# MIMXRT1011 register map
Vendor: nxp.com; File version: 1.0
CPU: CM7 r0p1, little endian, MPU, FPU, VTOR, 4 interrupt priority bits
Registers are 32-bit, read-write, reset 0x0 unless marked. A register's access mark holds for its fields unless they carry their own. Offsets are from the block's base; [hi:lo] are bit positions; {n}, {i} and the like mark numbered series; 'fields as' and 'values as' point back to an identical list.

## IOMUXC (part 2 of 2)
Base 0x401F8000; register names take the prefix IOMUXC_
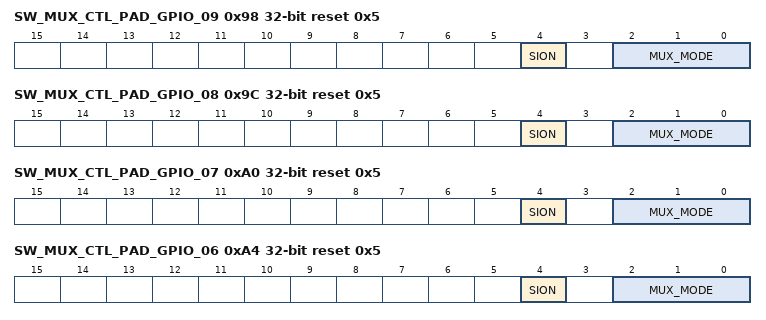
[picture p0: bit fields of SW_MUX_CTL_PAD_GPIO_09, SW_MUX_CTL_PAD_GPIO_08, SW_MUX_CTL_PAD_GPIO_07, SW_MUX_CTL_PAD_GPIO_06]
0x98 SW_MUX_CTL_PAD_GPIO_09 reset 0x5 — SW_MUX_CTL_PAD_GPIO_09 SW MUX Control Register
  [4] SION — Software Input On Field.
    0=DISABLED (Input Path is determined by functionality); 1=ENABLED (Force input path of pad GPIO_09)
  [2:0] MUX_MODE — MUX Mode Select Field.
    0=ALT0 (Select mux mode: ALT0 mux port: LPUART1_RXD of instance: LPUART1); 1=ALT1 (Select mux mode: ALT1 mux port: WDOG1_B of instance: WDOG1); 2=ALT2 (Select mux mode: ALT2 mux port: FLEXSPI_A_SS1_B of instance: FLEXSPI); 3=ALT3 (Select mux mode: ALT3 mux port: LPI2C2_SDA of instance: LPI2C2); 4=ALT4 (Select mux mode: ALT4 mux port: FLEXIO1_IO01 of instance: FLEXIO1); 5=ALT5 (Select mux mode: ALT5 mux port: GPIOMUX_IO09 of instance: GPIOMUX); 6=ALT6 (Select mux mode: ALT6 mux port: SPDIF_SR_CLK of instance: SPDIF)
0x9C SW_MUX_CTL_PAD_GPIO_08 reset 0x5 — SW_MUX_CTL_PAD_GPIO_08 SW MUX Control Register
  [4] SION — Software Input On Field.
    0=DISABLED (Input Path is determined by functionality); 1=ENABLED (Force input path of pad GPIO_08)
  [2:0] MUX_MODE — MUX Mode Select Field.
    0=ALT0 (Select mux mode: ALT0 mux port: SAI1_MCLK of instance: SAI1); 1=ALT1 (Select mux mode: ALT1 mux port: GPT1_CLK of instance: GPT1); 2=ALT2 (Select mux mode: ALT2 mux port: FLEXPWM1_PWM3_A of instance: FLEXPWM1); 3=ALT3 (Select mux mode: ALT3 mux port: LPUART3_TXD of instance: LPUART3); 4=ALT4 (Select mux mode: ALT4 mux port: FLEXIO1_IO00 of instance: FLEXIO1); 5=ALT5 (Select mux mode: ALT5 mux port: GPIOMUX_IO08 of instance: GPIOMUX); 6=ALT6 (Select mux mode: ALT6 mux port: LPUART1_CTS_B of instance: LPUART1)
0xA0 SW_MUX_CTL_PAD_GPIO_07 reset 0x5 — SW_MUX_CTL_PAD_GPIO_07 SW MUX Control Register
  [4] SION — Software Input On Field.
    0=DISABLED (Input Path is determined by functionality); 1=ENABLED (Force input path of pad GPIO_07)
  [2:0] MUX_MODE — MUX Mode Select Field.
    0=ALT0 (Select mux mode: ALT0 mux port: SAI1_TX_SYNC of instance: SAI1); 1=ALT1 (Select mux mode: ALT1 mux port: GPT1_COMPARE1 of instance: GPT1); 2=ALT2 (Select mux mode: ALT2 mux port: FLEXPWM1_PWM3_B of instance: FLEXPWM1); 3=ALT3 (Select mux mode: ALT3 mux port: LPUART3_RXD of instance: LPUART3); 4=ALT4 (Select mux mode: ALT4 mux port: SPDIF_LOCK of instance: SPDIF); 5=ALT5 (Select mux mode: ALT5 mux port: GPIOMUX_IO07 of instance: GPIOMUX); 6=ALT6 (Select mux mode: ALT6 mux port: LPUART1_RTS_B of instance: LPUART1)
0xA4 SW_MUX_CTL_PAD_GPIO_06 reset 0x5 — SW_MUX_CTL_PAD_GPIO_06 SW MUX Control Register
  [4] SION — Software Input On Field.
    0=DISABLED (Input Path is determined by functionality); 1=ENABLED (Force input path of pad GPIO_06)
  [2:0] MUX_MODE — MUX Mode Select Field.
    0=ALT0 (Select mux mode: ALT0 mux port: SAI1_TX_BCLK of instance: SAI1); 1=ALT1 (Select mux mode: ALT1 mux port: GPT1_CAPTURE1 of instance: GPT1); 2=ALT2 (Select mux mode: ALT2 mux port: FLEXPWM1_PWM2_A of instance: FLEXPWM1); 3=ALT3 (Select mux mode: ALT3 mux port: LPUART4_TXD of instance: LPUART4); 4=ALT4 (Select mux mode: ALT4 mux port: SPDIF_EXT_CLK of instance: SPDIF); 5=ALT5 (Select mux mode: ALT5 mux port: GPIOMUX_IO06 of instance: GPIOMUX)
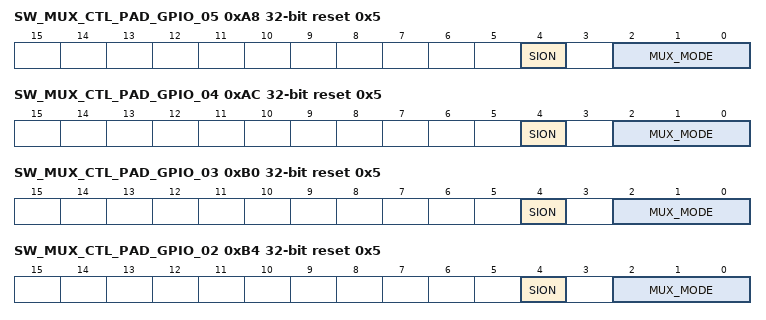
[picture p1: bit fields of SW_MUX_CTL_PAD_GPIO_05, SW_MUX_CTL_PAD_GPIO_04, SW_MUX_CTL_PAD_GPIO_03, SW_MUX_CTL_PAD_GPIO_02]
0xA8 SW_MUX_CTL_PAD_GPIO_05 reset 0x5 — SW_MUX_CTL_PAD_GPIO_05 SW MUX Control Register
  [4] SION — Software Input On Field.
    0=DISABLED (Input Path is determined by functionality); 1=ENABLED (Force input path of pad GPIO_05)
  [2:0] MUX_MODE — MUX Mode Select Field.
    0=ALT0 (Select mux mode: ALT0 mux port: SAI1_TX_DATA01 of instance: SAI1); 1=ALT1 (Select mux mode: ALT1 mux port: GPT1_COMPARE2 of instance: GPT1); 2=ALT2 (Select mux mode: ALT2 mux port: FLEXPWM1_PWM2_B of instance: FLEXPWM1); 3=ALT3 (Select mux mode: ALT3 mux port: LPUART4_RXD of instance: LPUART4); 4=ALT4 (Select mux mode: ALT4 mux port: SPDIF_OUT of instance: SPDIF); 5=ALT5 (Select mux mode: ALT5 mux port: GPIOMUX_IO05 of instance: GPIOMUX)
0xAC SW_MUX_CTL_PAD_GPIO_04 reset 0x5 — SW_MUX_CTL_PAD_GPIO_04 SW MUX Control Register
  [4] SION — Software Input On Field.
    0=DISABLED (Input Path is determined by functionality); 1=ENABLED (Force input path of pad GPIO_04)
  [2:0] MUX_MODE — MUX Mode Select Field.
    0=ALT0 (Select mux mode: ALT0 mux port: SAI1_TX_DATA00 of instance: SAI1); 1=ALT1 (Select mux mode: ALT1 mux port: GPT1_CAPTURE2 of instance: GPT1); 2=ALT2 (Select mux mode: ALT2 mux port: FLEXPWM1_PWM1_A of instance: FLEXPWM1); 4=ALT4 (Select mux mode: ALT4 mux port: SPDIF_IN of instance: SPDIF); 5=ALT5 (Select mux mode: ALT5 mux port: GPIOMUX_IO04 of instance: GPIOMUX)
0xB0 SW_MUX_CTL_PAD_GPIO_03 reset 0x5 — SW_MUX_CTL_PAD_GPIO_03 SW MUX Control Register
  [4] SION — Software Input On Field.
    0=DISABLED (Input Path is determined by functionality); 1=ENABLED (Force input path of pad GPIO_03)
  [2:0] MUX_MODE — MUX Mode Select Field.
    0=ALT0 (Select mux mode: ALT0 mux port: SAI1_RX_DATA00 of instance: SAI1); 1=ALT1 (Select mux mode: ALT1 mux port: GPT1_COMPARE3 of instance: GPT1); 2=ALT2 (Select mux mode: ALT2 mux port: FLEXPWM1_PWM1_B of instance: FLEXPWM1); 4=ALT4 (Select mux mode: ALT4 mux port: SPDIF_SR_CLK of instance: SPDIF); 5=ALT5 (Select mux mode: ALT5 mux port: GPIOMUX_IO03 of instance: GPIOMUX)
0xB4 SW_MUX_CTL_PAD_GPIO_02 reset 0x5 — SW_MUX_CTL_PAD_GPIO_02 SW MUX Control Register
  [4] SION — Software Input On Field.
    0=DISABLED (Input Path is determined by functionality); 1=ENABLED (Force input path of pad GPIO_02)
  [2:0] MUX_MODE — MUX Mode Select Field.
    0=ALT0 (Select mux mode: ALT0 mux port: SAI1_RX_SYNC of instance: SAI1); 1=ALT1 (Select mux mode: ALT1 mux port: WDOG2_B of instance: WDOG2); 2=ALT2 (Select mux mode: ALT2 mux port: FLEXPWM1_PWM0_A of instance: FLEXPWM1); 3=ALT3 (Select mux mode: ALT3 mux port: LPI2C1_SCL of instance: LPI2C1); 4=ALT4 (Select mux mode: ALT4 mux port: KPP_COL03 of instance: KPP); 5=ALT5 (Select mux mode: ALT5 mux port: GPIOMUX_IO02 of instance: GPIOMUX)
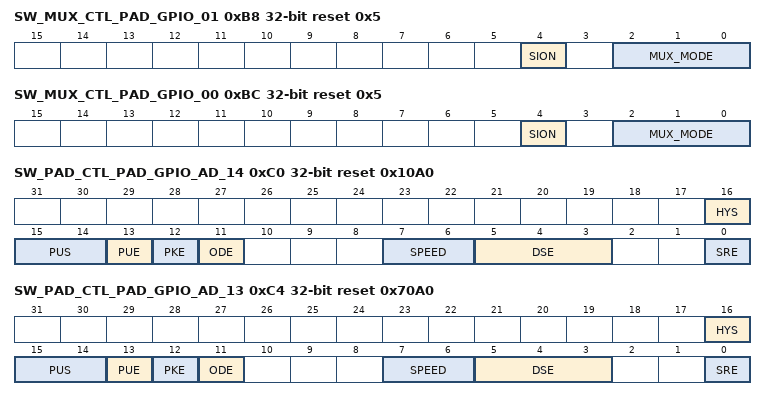
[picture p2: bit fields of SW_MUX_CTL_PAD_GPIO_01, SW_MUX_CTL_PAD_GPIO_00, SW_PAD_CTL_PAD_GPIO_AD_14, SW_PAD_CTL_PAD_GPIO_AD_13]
0xB8 SW_MUX_CTL_PAD_GPIO_01 reset 0x5 — SW_MUX_CTL_PAD_GPIO_01 SW MUX Control Register
  [4] SION — Software Input On Field.
    0=DISABLED (Input Path is determined by functionality); 1=ENABLED (Force input path of pad GPIO_01)
  [2:0] MUX_MODE — MUX Mode Select Field.
    0=ALT0 (Select mux mode: ALT0 mux port: SAI1_RX_BCLK of instance: SAI1); 1=ALT1 (Select mux mode: ALT1 mux port: WDOG1_ANY of instance: WDOG1); 2=ALT2 (Select mux mode: ALT2 mux port: FLEXPWM1_PWM0_B of instance: FLEXPWM1); 3=ALT3 (Select mux mode: ALT3 mux port: LPI2C1_SDA of instance: LPI2C1); 4=ALT4 (Select mux mode: ALT4 mux port: KPP_ROW03 of instance: KPP); 5=ALT5 (Select mux mode: ALT5 mux port: GPIOMUX_IO01 of instance: GPIOMUX)
0xBC SW_MUX_CTL_PAD_GPIO_00 reset 0x5 — SW_MUX_CTL_PAD_GPIO_00 SW MUX Control Register
  [4] SION — Software Input On Field.
    0=DISABLED (Input Path is determined by functionality); 1=ENABLED (Force input path of pad GPIO_00)
  [2:0] MUX_MODE — MUX Mode Select Field.
    0=ALT0 (Select mux mode: ALT0 mux port: FLEXSPI_B_DQS of instance: FLEXSPI); 1=ALT1 (Select mux mode: ALT1 mux port: SAI3_MCLK of instance: SAI3); 2=ALT2 (Select mux mode: ALT2 mux port: LPSPI2_PCS3 of instance: LPSPI2); 3=ALT3 (Select mux mode: ALT3 mux port: LPSPI1_PCS3 of instance: LPSPI1); 4=ALT4 (Select mux mode: ALT4 mux port: PIT_TRIGGER00 of instance: PIT); 5=ALT5 (Select mux mode: ALT5 mux port: GPIOMUX_IO00 of instance: GPIOMUX)
0xC0 SW_PAD_CTL_PAD_GPIO_AD_14 reset 0x10A0 — SW_PAD_CTL_PAD_GPIO_AD_14 SW PAD Control Register
  [16] HYS — Hyst. Enable Field
    0=HYS_0_Hysteresis_Disabled (Hysteresis Disabled); 1=HYS_1_Hysteresis_Enabled (Hysteresis Enabled)
  [15:14] PUS — Pull Up / Down Config. Field
    0=PUS_0_100K_Ohm_Pull_Down (100K Ohm Pull Down); 1=PUS_1_47K_Ohm_Pull_Up (47K Ohm Pull Up); 2=PUS_2_100K_Ohm_Pull_Up (100K Ohm Pull Up); 3=PUS_3_22K_Ohm_Pull_Up (22K Ohm Pull Up)
  [13] PUE — Pull / Keep Select Field
    0=PUE_0_Keeper (Keeper); 1=PUE_1_Pull (Pull)
  [12] PKE — Pull / Keep Enable Field
    0=PKE_0_Pull_Keeper_Disabled (Pull/Keeper Disabled); 1=PKE_1_Pull_Keeper_Enabled (Pull/Keeper Enabled)
  [11] ODE — Open Drain Enable Field
    0=ODE_0_Open_Drain_Disabled (Open Drain Disabled); 1=ODE_1_Open_Drain_Enabled (Open Drain Enabled)
  [7:6] SPEED
    0=SPEED_0_low_50MHz (low(50MHz)); 1=SPEED_1_medium_100MHz (medium(100MHz)); 2=SPEED_2_fast_150MHz (fast(150MHz)); 3=SPEED_3_max_200MHz (max(200MHz))
  [5:3] DSE — Drive Strength Field
    0=DSE_0_output_driver_disabled_ (output driver disabled;); 1=DSE_1_R0_150_Ohm___3_3V__260_Ohm_1_8V__240_Ohm_for_DDR_ (R0(150 Ohm @ 3.3V, 260 Ohm@1.8V, 240 Ohm for DDR)); {v}=DSE_{v}_R0_{v} (R0/{v}) (v=2..7)
  [0] SRE — Slew Rate Field
    0=SRE_0_Slow_Slew_Rate (Slow Slew Rate); 1=SRE_1_Fast_Slew_Rate (Fast Slew Rate)
0xC4 SW_PAD_CTL_PAD_GPIO_AD_13 reset 0x70A0 — SW_PAD_CTL_PAD_GPIO_AD_13 SW PAD Control Register
  fields as SW_PAD_CTL_PAD_GPIO_AD_14
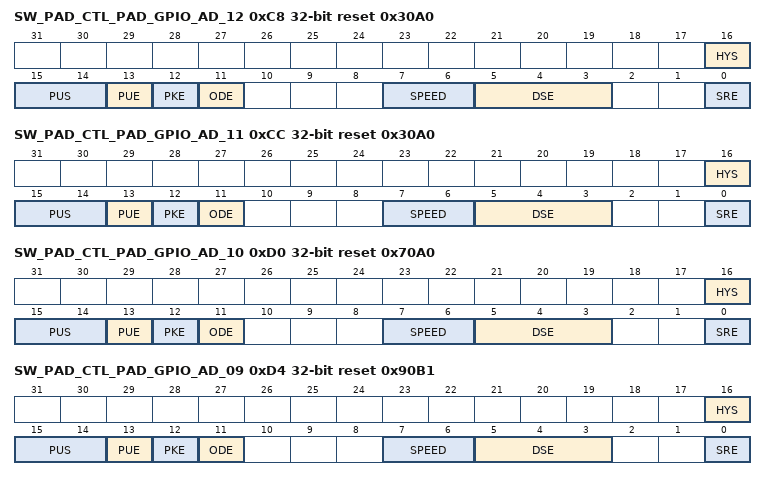
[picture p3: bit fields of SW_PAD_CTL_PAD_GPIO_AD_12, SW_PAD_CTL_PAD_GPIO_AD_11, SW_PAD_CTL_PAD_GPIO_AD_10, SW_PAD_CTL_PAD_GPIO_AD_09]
0xC8 SW_PAD_CTL_PAD_GPIO_AD_12 reset 0x30A0 — SW_PAD_CTL_PAD_GPIO_AD_12 SW PAD Control Register
  fields as SW_PAD_CTL_PAD_GPIO_AD_14
0xCC SW_PAD_CTL_PAD_GPIO_AD_11 reset 0x30A0 — SW_PAD_CTL_PAD_GPIO_AD_11 SW PAD Control Register
  fields as SW_PAD_CTL_PAD_GPIO_AD_14
0xD0 SW_PAD_CTL_PAD_GPIO_AD_10 reset 0x70A0 — SW_PAD_CTL_PAD_GPIO_AD_10 SW PAD Control Register
  fields as SW_PAD_CTL_PAD_GPIO_AD_14
0xD4 SW_PAD_CTL_PAD_GPIO_AD_09 reset 0x90B1 — SW_PAD_CTL_PAD_GPIO_AD_09 SW PAD Control Register
  fields as SW_PAD_CTL_PAD_GPIO_AD_14
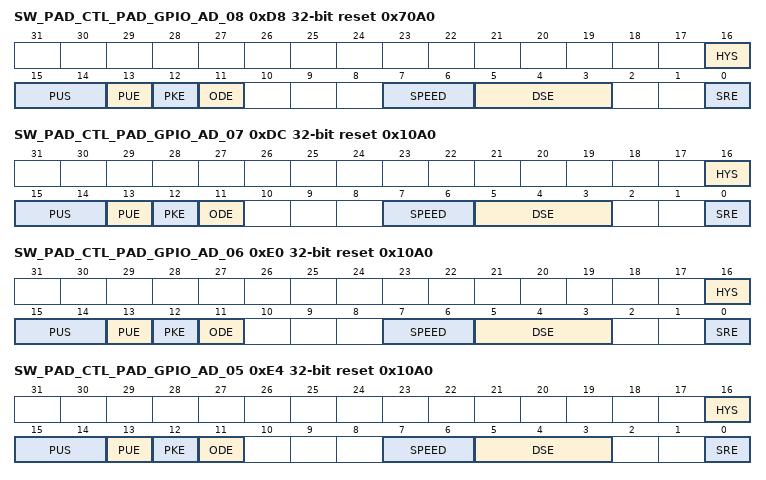
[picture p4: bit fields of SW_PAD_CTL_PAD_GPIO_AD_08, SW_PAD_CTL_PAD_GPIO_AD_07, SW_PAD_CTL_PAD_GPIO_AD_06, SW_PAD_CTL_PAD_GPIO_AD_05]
0xD8 SW_PAD_CTL_PAD_GPIO_AD_08 reset 0x70A0 — SW_PAD_CTL_PAD_GPIO_AD_08 SW PAD Control Register
  fields as SW_PAD_CTL_PAD_GPIO_AD_14
0xDC SW_PAD_CTL_PAD_GPIO_AD_07 reset 0x10A0 — SW_PAD_CTL_PAD_GPIO_AD_07 SW PAD Control Register
  fields as SW_PAD_CTL_PAD_GPIO_AD_14
0xE0 SW_PAD_CTL_PAD_GPIO_AD_06 reset 0x10A0 — SW_PAD_CTL_PAD_GPIO_AD_06 SW PAD Control Register
  fields as SW_PAD_CTL_PAD_GPIO_AD_14
0xE4 SW_PAD_CTL_PAD_GPIO_AD_05 reset 0x10A0 — SW_PAD_CTL_PAD_GPIO_AD_05 SW PAD Control Register
  fields as SW_PAD_CTL_PAD_GPIO_AD_14
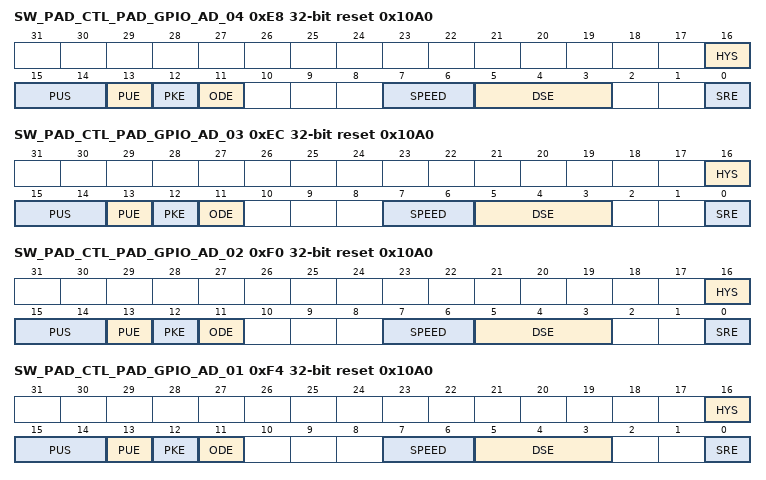
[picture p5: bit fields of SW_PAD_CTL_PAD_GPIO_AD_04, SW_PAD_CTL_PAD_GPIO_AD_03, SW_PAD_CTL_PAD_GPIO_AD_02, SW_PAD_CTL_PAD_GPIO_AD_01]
0xE8 SW_PAD_CTL_PAD_GPIO_AD_04 reset 0x10A0 — SW_PAD_CTL_PAD_GPIO_AD_04 SW PAD Control Register
  fields as SW_PAD_CTL_PAD_GPIO_AD_14
0xEC SW_PAD_CTL_PAD_GPIO_AD_03 reset 0x10A0 — SW_PAD_CTL_PAD_GPIO_AD_03 SW PAD Control Register
  fields as SW_PAD_CTL_PAD_GPIO_AD_14
0xF0 SW_PAD_CTL_PAD_GPIO_AD_02 reset 0x10A0 — SW_PAD_CTL_PAD_GPIO_AD_02 SW PAD Control Register
  fields as SW_PAD_CTL_PAD_GPIO_AD_14
0xF4 SW_PAD_CTL_PAD_GPIO_AD_01 reset 0x10A0 — SW_PAD_CTL_PAD_GPIO_AD_01 SW PAD Control Register
  fields as SW_PAD_CTL_PAD_GPIO_AD_14
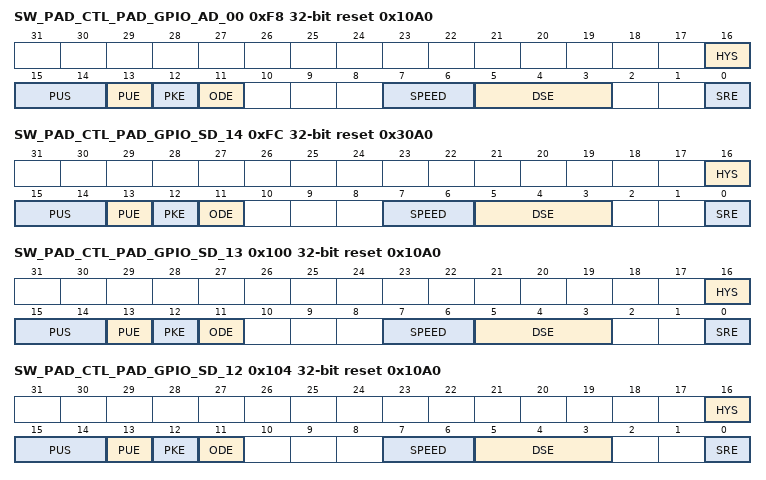
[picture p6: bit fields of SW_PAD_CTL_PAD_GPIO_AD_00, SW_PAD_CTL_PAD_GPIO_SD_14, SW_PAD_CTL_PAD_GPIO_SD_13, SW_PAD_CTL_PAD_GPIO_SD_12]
0xF8 SW_PAD_CTL_PAD_GPIO_AD_00 reset 0x10A0 — SW_PAD_CTL_PAD_GPIO_AD_00 SW PAD Control Register
  fields as SW_PAD_CTL_PAD_GPIO_AD_14
0xFC SW_PAD_CTL_PAD_GPIO_SD_14 reset 0x30A0 — SW_PAD_CTL_PAD_GPIO_SD_14 SW PAD Control Register
  fields as SW_PAD_CTL_PAD_GPIO_AD_14
0x100 SW_PAD_CTL_PAD_GPIO_SD_13 reset 0x10A0 — SW_PAD_CTL_PAD_GPIO_SD_13 SW PAD Control Register
  fields as SW_PAD_CTL_PAD_GPIO_AD_14
0x104 SW_PAD_CTL_PAD_GPIO_SD_12 reset 0x10A0 — SW_PAD_CTL_PAD_GPIO_SD_12 SW PAD Control Register
  fields as SW_PAD_CTL_PAD_GPIO_AD_14
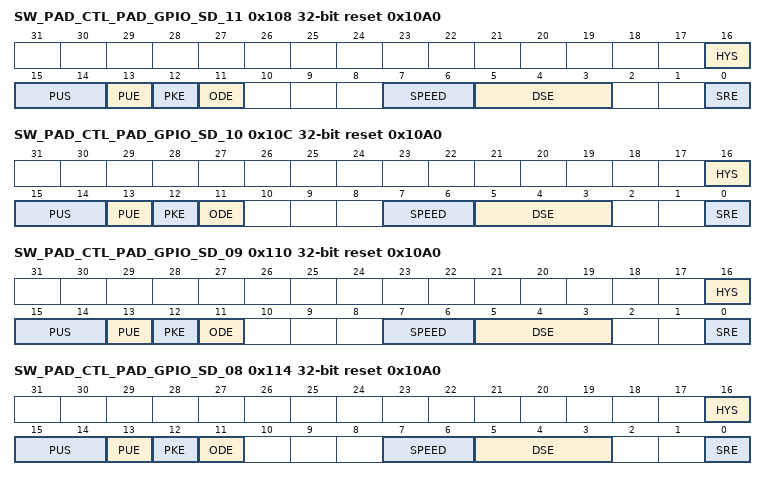
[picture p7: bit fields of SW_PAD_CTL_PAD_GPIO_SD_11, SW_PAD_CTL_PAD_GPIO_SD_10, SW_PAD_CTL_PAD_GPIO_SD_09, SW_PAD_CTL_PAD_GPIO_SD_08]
0x108 SW_PAD_CTL_PAD_GPIO_SD_11 reset 0x10A0 — SW_PAD_CTL_PAD_GPIO_SD_11 SW PAD Control Register
  fields as SW_PAD_CTL_PAD_GPIO_AD_14
0x10C SW_PAD_CTL_PAD_GPIO_SD_10 reset 0x10A0 — SW_PAD_CTL_PAD_GPIO_SD_10 SW PAD Control Register
  fields as SW_PAD_CTL_PAD_GPIO_AD_14
0x110 SW_PAD_CTL_PAD_GPIO_SD_09 reset 0x10A0 — SW_PAD_CTL_PAD_GPIO_SD_09 SW PAD Control Register
  fields as SW_PAD_CTL_PAD_GPIO_AD_14
0x114 SW_PAD_CTL_PAD_GPIO_SD_08 reset 0x10A0 — SW_PAD_CTL_PAD_GPIO_SD_08 SW PAD Control Register
  fields as SW_PAD_CTL_PAD_GPIO_AD_14
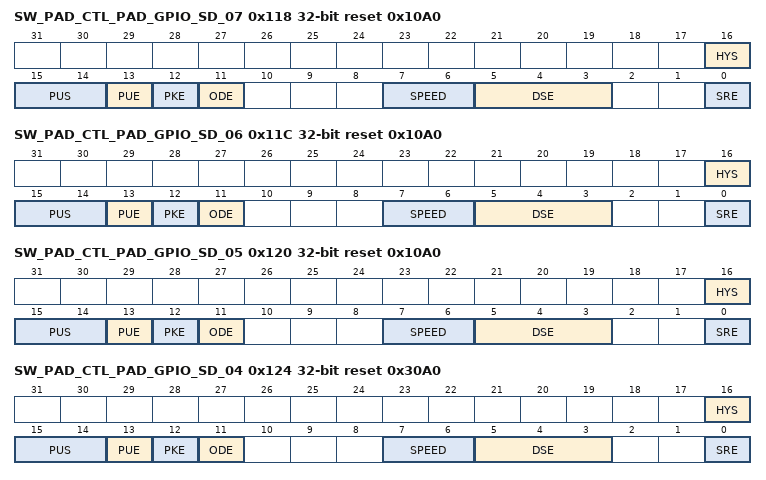
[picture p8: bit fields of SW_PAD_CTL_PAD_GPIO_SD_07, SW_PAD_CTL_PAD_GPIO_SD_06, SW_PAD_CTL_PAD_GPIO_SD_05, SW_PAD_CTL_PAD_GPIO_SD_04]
0x118 SW_PAD_CTL_PAD_GPIO_SD_07 reset 0x10A0 — SW_PAD_CTL_PAD_GPIO_SD_07 SW PAD Control Register
  fields as SW_PAD_CTL_PAD_GPIO_AD_14
0x11C SW_PAD_CTL_PAD_GPIO_SD_06 reset 0x10A0 — SW_PAD_CTL_PAD_GPIO_SD_06 SW PAD Control Register
  fields as SW_PAD_CTL_PAD_GPIO_AD_14
0x120 SW_PAD_CTL_PAD_GPIO_SD_05 reset 0x10A0 — SW_PAD_CTL_PAD_GPIO_SD_05 SW PAD Control Register
  fields as SW_PAD_CTL_PAD_GPIO_AD_14
0x124 SW_PAD_CTL_PAD_GPIO_SD_04 reset 0x30A0 — SW_PAD_CTL_PAD_GPIO_SD_04 SW PAD Control Register
  fields as SW_PAD_CTL_PAD_GPIO_AD_14
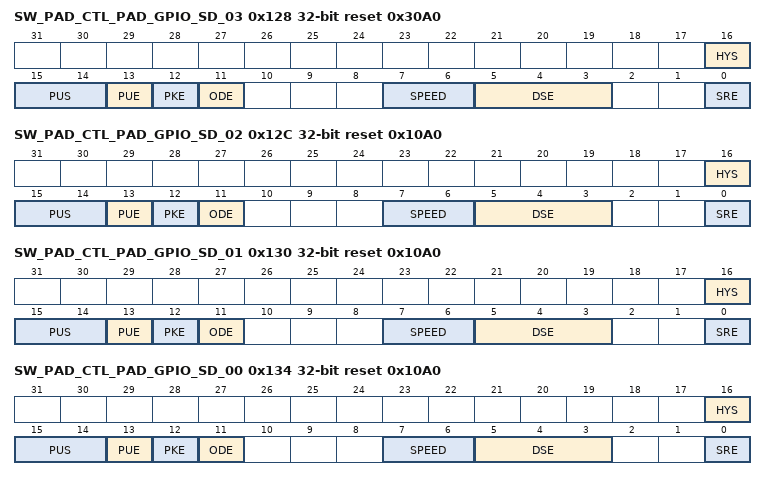
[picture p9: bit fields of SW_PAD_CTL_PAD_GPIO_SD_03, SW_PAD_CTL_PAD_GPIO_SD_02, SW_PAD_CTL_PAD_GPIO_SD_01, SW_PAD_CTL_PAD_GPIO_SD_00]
0x128 SW_PAD_CTL_PAD_GPIO_SD_03 reset 0x30A0 — SW_PAD_CTL_PAD_GPIO_SD_03 SW PAD Control Register
  fields as SW_PAD_CTL_PAD_GPIO_AD_14
0x12C SW_PAD_CTL_PAD_GPIO_SD_02 reset 0x10A0 — SW_PAD_CTL_PAD_GPIO_SD_02 SW PAD Control Register
  fields as SW_PAD_CTL_PAD_GPIO_AD_14
0x130 SW_PAD_CTL_PAD_GPIO_SD_01 reset 0x10A0 — SW_PAD_CTL_PAD_GPIO_SD_01 SW PAD Control Register
  fields as SW_PAD_CTL_PAD_GPIO_AD_14
0x134 SW_PAD_CTL_PAD_GPIO_SD_00 reset 0x10A0 — SW_PAD_CTL_PAD_GPIO_SD_00 SW PAD Control Register
  fields as SW_PAD_CTL_PAD_GPIO_AD_14
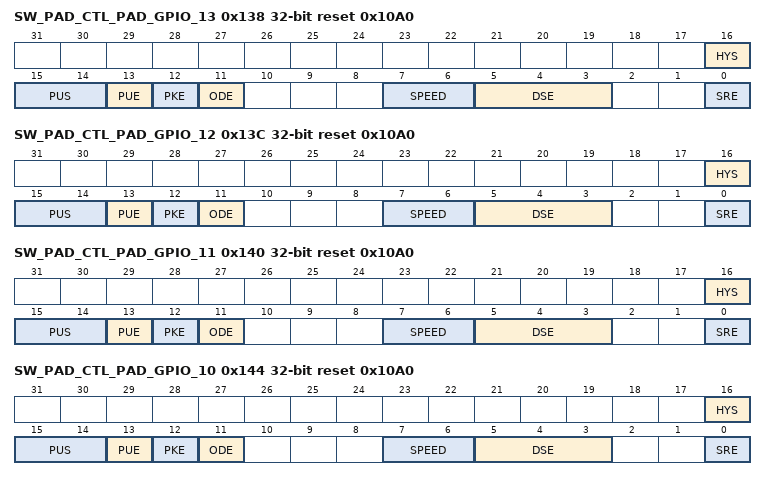
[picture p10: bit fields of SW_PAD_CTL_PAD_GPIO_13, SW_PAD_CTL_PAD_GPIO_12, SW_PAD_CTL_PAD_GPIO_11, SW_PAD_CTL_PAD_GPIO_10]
0x138 SW_PAD_CTL_PAD_GPIO_13 reset 0x10A0 — SW_PAD_CTL_PAD_GPIO_13 SW PAD Control Register
  fields as SW_PAD_CTL_PAD_GPIO_AD_14
0x13C SW_PAD_CTL_PAD_GPIO_12 reset 0x10A0 — SW_PAD_CTL_PAD_GPIO_12 SW PAD Control Register
  fields as SW_PAD_CTL_PAD_GPIO_AD_14
0x140 SW_PAD_CTL_PAD_GPIO_11 reset 0x10A0 — SW_PAD_CTL_PAD_GPIO_11 SW PAD Control Register
  fields as SW_PAD_CTL_PAD_GPIO_AD_14
0x144 SW_PAD_CTL_PAD_GPIO_10 reset 0x10A0 — SW_PAD_CTL_PAD_GPIO_10 SW PAD Control Register
  fields as SW_PAD_CTL_PAD_GPIO_AD_14
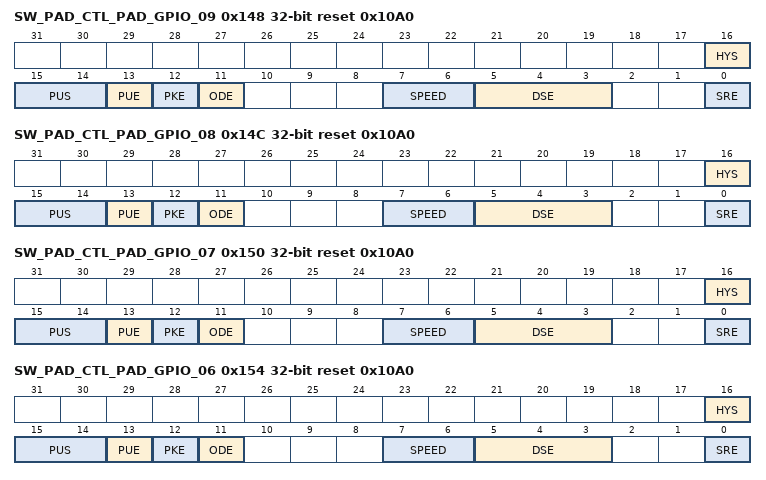
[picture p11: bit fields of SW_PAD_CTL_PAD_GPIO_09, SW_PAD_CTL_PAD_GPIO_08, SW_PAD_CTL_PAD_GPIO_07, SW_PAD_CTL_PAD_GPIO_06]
0x148 SW_PAD_CTL_PAD_GPIO_09 reset 0x10A0 — SW_PAD_CTL_PAD_GPIO_09 SW PAD Control Register
  fields as SW_PAD_CTL_PAD_GPIO_AD_14
0x14C SW_PAD_CTL_PAD_GPIO_08 reset 0x10A0 — SW_PAD_CTL_PAD_GPIO_08 SW PAD Control Register
  fields as SW_PAD_CTL_PAD_GPIO_AD_14
0x150 SW_PAD_CTL_PAD_GPIO_07 reset 0x10A0 — SW_PAD_CTL_PAD_GPIO_07 SW PAD Control Register
  fields as SW_PAD_CTL_PAD_GPIO_AD_14
0x154 SW_PAD_CTL_PAD_GPIO_06 reset 0x10A0 — SW_PAD_CTL_PAD_GPIO_06 SW PAD Control Register
  fields as SW_PAD_CTL_PAD_GPIO_AD_14
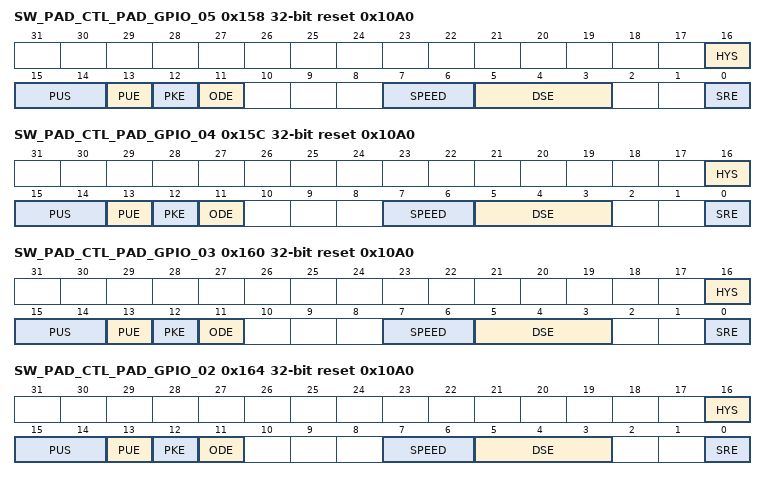
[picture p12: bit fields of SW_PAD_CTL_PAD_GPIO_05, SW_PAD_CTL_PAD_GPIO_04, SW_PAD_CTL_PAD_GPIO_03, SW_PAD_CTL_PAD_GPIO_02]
0x158 SW_PAD_CTL_PAD_GPIO_05 reset 0x10A0 — SW_PAD_CTL_PAD_GPIO_05 SW PAD Control Register
  fields as SW_PAD_CTL_PAD_GPIO_AD_14
0x15C SW_PAD_CTL_PAD_GPIO_04 reset 0x10A0 — SW_PAD_CTL_PAD_GPIO_04 SW PAD Control Register
  fields as SW_PAD_CTL_PAD_GPIO_AD_14
0x160 SW_PAD_CTL_PAD_GPIO_03 reset 0x10A0 — SW_PAD_CTL_PAD_GPIO_03 SW PAD Control Register
  fields as SW_PAD_CTL_PAD_GPIO_AD_14
0x164 SW_PAD_CTL_PAD_GPIO_02 reset 0x10A0 — SW_PAD_CTL_PAD_GPIO_02 SW PAD Control Register
  fields as SW_PAD_CTL_PAD_GPIO_AD_14
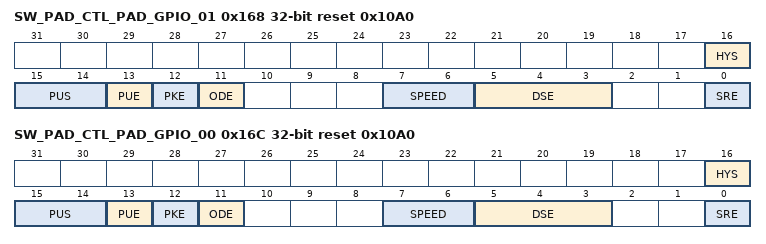
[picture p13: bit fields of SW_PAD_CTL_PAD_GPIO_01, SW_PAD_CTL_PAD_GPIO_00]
0x168 SW_PAD_CTL_PAD_GPIO_01 reset 0x10A0 — SW_PAD_CTL_PAD_GPIO_01 SW PAD Control Register
  fields as SW_PAD_CTL_PAD_GPIO_AD_14
0x16C SW_PAD_CTL_PAD_GPIO_00 reset 0x10A0 — SW_PAD_CTL_PAD_GPIO_00 SW PAD Control Register
  fields as SW_PAD_CTL_PAD_GPIO_AD_14
0x170 USB_OTG_ID_SELECT_INPUT — USB_OTG_ID_SELECT_INPUT DAISY Register
  [0] DAISY — Selecting Pads Involved in Daisy Chain.
    0=GPIO_AD_10_ALT6 (Selecting Pad: GPIO_AD_10 for Mode: ALT6); 1=GPIO_13_ALT3 (Selecting Pad: GPIO_13 for Mode: ALT3)
0x174 FLEXPWM1_PWMA_SELECT_INPUT_0 — FLEXPWM1_PWMA_SELECT_INPUT_0 DAISY Register
  [0] DAISY — Selecting Pads Involved in Daisy Chain.
    0=GPIO_SD_02_ALT2 (Selecting Pad: GPIO_SD_02 for Mode: ALT2); 1=GPIO_02_ALT2 (Selecting Pad: GPIO_02 for Mode: ALT2)
0x178 FLEXPWM1_PWMA_SELECT_INPUT_1 — FLEXPWM1_PWMA_SELECT_INPUT_1 DAISY Register
  [0] DAISY — Selecting Pads Involved in Daisy Chain.
    0=GPIO_SD_04_ALT2 (Selecting Pad: GPIO_SD_04 for Mode: ALT2); 1=GPIO_04_ALT2 (Selecting Pad: GPIO_04 for Mode: ALT2)
0x17C FLEXPWM1_PWMA_SELECT_INPUT_2 — FLEXPWM1_PWMA_SELECT_INPUT_2 DAISY Register
  [0] DAISY — Selecting Pads Involved in Daisy Chain.
    0=GPIO_AD_04_ALT2 (Selecting Pad: GPIO_AD_04 for Mode: ALT2); 1=GPIO_06_ALT2 (Selecting Pad: GPIO_06 for Mode: ALT2)
0x180 FLEXPWM1_PWMA_SELECT_INPUT_3 — FLEXPWM1_PWMA_SELECT_INPUT_3 DAISY Register
  [0] DAISY — Selecting Pads Involved in Daisy Chain.
    0=GPIO_AD_06_ALT2 (Selecting Pad: GPIO_AD_06 for Mode: ALT2); 1=GPIO_08_ALT2 (Selecting Pad: GPIO_08 for Mode: ALT2)
0x184 FLEXPWM1_PWMB_SELECT_INPUT_0 — FLEXPWM1_PWMB_SELECT_INPUT_0 DAISY Register
  [0] DAISY — Selecting Pads Involved in Daisy Chain.
    0=GPIO_SD_01_ALT2 (Selecting Pad: GPIO_SD_01 for Mode: ALT2); 1=GPIO_01_ALT2 (Selecting Pad: GPIO_01 for Mode: ALT2)
0x188 FLEXPWM1_PWMB_SELECT_INPUT_1 — FLEXPWM1_PWMB_SELECT_INPUT_1 DAISY Register
  [0] DAISY — Selecting Pads Involved in Daisy Chain.
    0=GPIO_SD_03_ALT2 (Selecting Pad: GPIO_SD_03 for Mode: ALT2); 1=GPIO_03_ALT2 (Selecting Pad: GPIO_03 for Mode: ALT2)
0x18C FLEXPWM1_PWMB_SELECT_INPUT_2 — FLEXPWM1_PWMB_SELECT_INPUT_2 DAISY Register
  [0] DAISY — Selecting Pads Involved in Daisy Chain.
    0=GPIO_AD_03_ALT2 (Selecting Pad: GPIO_AD_03 for Mode: ALT2); 1=GPIO_05_ALT2 (Selecting Pad: GPIO_05 for Mode: ALT2)
0x190 FLEXPWM1_PWMB_SELECT_INPUT_3 — FLEXPWM1_PWMB_SELECT_INPUT_3 DAISY Register
  [0] DAISY — Selecting Pads Involved in Daisy Chain.
    0=GPIO_AD_05_ALT2 (Selecting Pad: GPIO_AD_05 for Mode: ALT2); 1=GPIO_07_ALT2 (Selecting Pad: GPIO_07 for Mode: ALT2)
0x194 FLEXSPI_DQS_FA_SELECT_INPUT — FLEXSPI_DQS_FA_SELECT_INPUT DAISY Register
  [0] DAISY — Selecting Pads Involved in Daisy Chain.
    0=GPIO_SD_14_ALT0 (Selecting Pad: GPIO_SD_14 for Mode: ALT0); 1=GPIO_SD_12_ALT0 (Selecting Pad: GPIO_SD_12 for Mode: ALT0)
0x198 FLEXSPI_DQS_FB_SELECT_INPUT — FLEXSPI_DQS_FB_SELECT_INPUT DAISY Register
  [0] DAISY — Selecting Pads Involved in Daisy Chain.
    0=GPIO_SD_14_ALT1 (Selecting Pad: GPIO_SD_14 for Mode: ALT1); 1=GPIO_00_ALT0 (Selecting Pad: GPIO_00 for Mode: ALT0)
0x19C KPP_COL_SELECT_INPUT_0 — KPP_COL_SELECT_INPUT_0 DAISY Register
  [0] DAISY — Selecting Pads Involved in Daisy Chain.
    0=GPIO_AD_14_ALT2 (Selecting Pad: GPIO_AD_14 for Mode: ALT2); 1=GPIO_12_ALT2 (Selecting Pad: GPIO_12 for Mode: ALT2)
0x1A0 KPP_COL_SELECT_INPUT_1 — KPP_COL_SELECT_INPUT_1 DAISY Register
  [0] DAISY — Selecting Pads Involved in Daisy Chain.
    0=GPIO_AD_12_ALT2 (Selecting Pad: GPIO_AD_12 for Mode: ALT2); 1=GPIO_AD_06_ALT3 (Selecting Pad: GPIO_AD_06 for Mode: ALT3)
0x1A4 KPP_COL_SELECT_INPUT_2 — KPP_COL_SELECT_INPUT_2 DAISY Register
  [0] DAISY — Selecting Pads Involved in Daisy Chain.
    0=GPIO_AD_10_ALT2 (Selecting Pad: GPIO_AD_10 for Mode: ALT2); 1=GPIO_AD_04_ALT3 (Selecting Pad: GPIO_AD_04 for Mode: ALT3)
0x1A8 KPP_COL_SELECT_INPUT_3 — KPP_COL_SELECT_INPUT_3 DAISY Register
  [0] DAISY — Selecting Pads Involved in Daisy Chain.
    0=GPIO_AD_00_ALT2 (Selecting Pad: GPIO_AD_00 for Mode: ALT2); 1=GPIO_02_ALT4 (Selecting Pad: GPIO_02 for Mode: ALT4)
0x1AC KPP_ROW_SELECT_INPUT_0 — KPP_ROW_SELECT_INPUT_0 DAISY Register
  [0] DAISY — Selecting Pads Involved in Daisy Chain.
    0=GPIO_AD_13_ALT2 (Selecting Pad: GPIO_AD_13 for Mode: ALT2); 1=GPIO_11_ALT2 (Selecting Pad: GPIO_11 for Mode: ALT2)
0x1B0 KPP_ROW_SELECT_INPUT_1 — KPP_ROW_SELECT_INPUT_1 DAISY Register
  [0] DAISY — Selecting Pads Involved in Daisy Chain.
    0=GPIO_AD_11_ALT2 (Selecting Pad: GPIO_AD_11 for Mode: ALT2); 1=GPIO_AD_05_ALT3 (Selecting Pad: GPIO_AD_05 for Mode: ALT3)
0x1B4 KPP_ROW_SELECT_INPUT_2 — KPP_ROW_SELECT_INPUT_2 DAISY Register
  [0] DAISY — Selecting Pads Involved in Daisy Chain.
    0=GPIO_AD_09_ALT2 (Selecting Pad: GPIO_AD_09 for Mode: ALT2); 1=GPIO_AD_03_ALT3 (Selecting Pad: GPIO_AD_03 for Mode: ALT3)
0x1B8 KPP_ROW_SELECT_INPUT_3 — KPP_ROW_SELECT_INPUT_3 DAISY Register
  [0] DAISY — Selecting Pads Involved in Daisy Chain.
    0=GPIO_13_ALT2 (Selecting Pad: GPIO_13 for Mode: ALT2); 1=GPIO_01_ALT4 (Selecting Pad: GPIO_01 for Mode: ALT4)
0x1BC LPI2C1_HREQ_SELECT_INPUT — LPI2C1_HREQ_SELECT_INPUT DAISY Register
  [0] DAISY — Selecting Pads Involved in Daisy Chain.
    0=GPIO_AD_06_ALT6 (Selecting Pad: GPIO_AD_06 for Mode: ALT6); 1=GPIO_10_ALT1 (Selecting Pad: GPIO_10 for Mode: ALT1)
0x1C0 LPI2C1_SCL_SELECT_INPUT — LPI2C1_SCL_SELECT_INPUT DAISY Register
  [1:0] DAISY — Selecting Pads Involved in Daisy Chain.
    0=GPIO_AD_14_ALT0 (Selecting Pad: GPIO_AD_14 for Mode: ALT0); 1=GPIO_SD_06_ALT1 (Selecting Pad: GPIO_SD_06 for Mode: ALT1); 2=GPIO_12_ALT1 (Selecting Pad: GPIO_12 for Mode: ALT1); 3=GPIO_02_ALT3 (Selecting Pad: GPIO_02 for Mode: ALT3)
0x1C4 LPI2C1_SDA_SELECT_INPUT — LPI2C1_SDA_SELECT_INPUT DAISY Register
  [1:0] DAISY — Selecting Pads Involved in Daisy Chain.
    0=GPIO_AD_13_ALT0 (Selecting Pad: GPIO_AD_13 for Mode: ALT0); 1=GPIO_SD_05_ALT1 (Selecting Pad: GPIO_SD_05 for Mode: ALT1); 2=GPIO_11_ALT1 (Selecting Pad: GPIO_11 for Mode: ALT1); 3=GPIO_01_ALT3 (Selecting Pad: GPIO_01 for Mode: ALT3)
0x1C8 LPI2C2_SCL_SELECT_INPUT — LPI2C2_SCL_SELECT_INPUT DAISY Register
  [1:0] DAISY — Selecting Pads Involved in Daisy Chain.
    0=GPIO_AD_08_ALT0 (Selecting Pad: GPIO_AD_08 for Mode: ALT0); 1=GPIO_AD_02_ALT3 (Selecting Pad: GPIO_AD_02 for Mode: ALT3); 2=GPIO_SD_08_ALT1 (Selecting Pad: GPIO_SD_08 for Mode: ALT1); 3=GPIO_10_ALT3 (Selecting Pad: GPIO_10 for Mode: ALT3)
0x1CC LPI2C2_SDA_SELECT_INPUT — LPI2C2_SDA_SELECT_INPUT DAISY Register
  [1:0] DAISY — Selecting Pads Involved in Daisy Chain.
    0=GPIO_AD_07_ALT0 (Selecting Pad: GPIO_AD_07 for Mode: ALT0); 1=GPIO_AD_01_ALT3 (Selecting Pad: GPIO_AD_01 for Mode: ALT3); 2=GPIO_SD_07_ALT1 (Selecting Pad: GPIO_SD_07 for Mode: ALT1); 3=GPIO_09_ALT3 (Selecting Pad: GPIO_09 for Mode: ALT3)
0x1D0 LPSPI1_PCS_SELECT_INPUT_0 — LPSPI1_PCS_SELECT_INPUT_0 DAISY Register
  [0] DAISY — Selecting Pads Involved in Daisy Chain.
    0=GPIO_AD_05_ALT0 (Selecting Pad: GPIO_AD_05 for Mode: ALT0); 1=GPIO_SD_07_ALT2 (Selecting Pad: GPIO_SD_07 for Mode: ALT2)
0x1D4 LPSPI1_SCK_SELECT_INPUT — LPSPI1_SCK_SELECT_INPUT DAISY Register
  [0] DAISY — Selecting Pads Involved in Daisy Chain.
    0=GPIO_AD_06_ALT0 (Selecting Pad: GPIO_AD_06 for Mode: ALT0); 1=GPIO_SD_08_ALT2 (Selecting Pad: GPIO_SD_08 for Mode: ALT2)
0x1D8 LPSPI1_SDI_SELECT_INPUT — LPSPI1_SDI_SELECT_INPUT DAISY Register
  [0] DAISY — Selecting Pads Involved in Daisy Chain.
    0=GPIO_AD_03_ALT0 (Selecting Pad: GPIO_AD_03 for Mode: ALT0); 1=GPIO_SD_05_ALT2 (Selecting Pad: GPIO_SD_05 for Mode: ALT2)
0x1DC LPSPI1_SDO_SELECT_INPUT — LPSPI1_SDO_SELECT_INPUT DAISY Register
  [0] DAISY — Selecting Pads Involved in Daisy Chain.
    0=GPIO_AD_04_ALT0 (Selecting Pad: GPIO_AD_04 for Mode: ALT0); 1=GPIO_SD_06_ALT2 (Selecting Pad: GPIO_SD_06 for Mode: ALT2)
0x1E0 LPSPI2_PCS_SELECT_INPUT_0 — LPSPI2_PCS_SELECT_INPUT_0 DAISY Register
  [0] DAISY — Selecting Pads Involved in Daisy Chain.
    0=GPIO_AD_11_ALT0 (Selecting Pad: GPIO_AD_11 for Mode: ALT0); 1=GPIO_SD_12_ALT1 (Selecting Pad: GPIO_SD_12 for Mode: ALT1)
0x1E4 LPSPI2_SCK_SELECT_INPUT — LPSPI2_SCK_SELECT_INPUT DAISY Register
  [0] DAISY — Selecting Pads Involved in Daisy Chain.
    0=GPIO_AD_12_ALT0 (Selecting Pad: GPIO_AD_12 for Mode: ALT0); 1=GPIO_SD_11_ALT1 (Selecting Pad: GPIO_SD_11 for Mode: ALT1)
0x1E8 LPSPI2_SDI_SELECT_INPUT — LPSPI2_SDI_SELECT_INPUT DAISY Register
  [0] DAISY — Selecting Pads Involved in Daisy Chain.
    0=GPIO_AD_09_ALT0 (Selecting Pad: GPIO_AD_09 for Mode: ALT0); 1=GPIO_SD_09_ALT1 (Selecting Pad: GPIO_SD_09 for Mode: ALT1)
0x1EC LPSPI2_SDO_SELECT_INPUT — LPSPI2_SDO_SELECT_INPUT DAISY Register
  [0] DAISY — Selecting Pads Involved in Daisy Chain.
    0=GPIO_AD_10_ALT0 (Selecting Pad: GPIO_AD_10 for Mode: ALT0); 1=GPIO_SD_10_ALT1 (Selecting Pad: GPIO_SD_10 for Mode: ALT1)
0x1F0 LPUART1_RXD_SELECT_INPUT — LPUART1_RXD_SELECT_INPUT DAISY Register
  [0] DAISY — Selecting Pads Involved in Daisy Chain.
    0=GPIO_SD_11_ALT2 (Selecting Pad: GPIO_SD_11 for Mode: ALT2); 1=GPIO_09_ALT0 (Selecting Pad: GPIO_09 for Mode: ALT0)
0x1F4 LPUART1_TXD_SELECT_INPUT — LPUART1_TXD_SELECT_INPUT DAISY Register
  [0] DAISY — Selecting Pads Involved in Daisy Chain.
    0=GPIO_SD_12_ALT2 (Selecting Pad: GPIO_SD_12 for Mode: ALT2); 1=GPIO_10_ALT0 (Selecting Pad: GPIO_10 for Mode: ALT0)
0x1F8 LPUART2_RXD_SELECT_INPUT — LPUART2_RXD_SELECT_INPUT DAISY Register
  [0] DAISY — Selecting Pads Involved in Daisy Chain.
    0=GPIO_SD_09_ALT2 (Selecting Pad: GPIO_SD_09 for Mode: ALT2); 1=GPIO_13_ALT0 (Selecting Pad: GPIO_13 for Mode: ALT0)
0x1FC LPUART2_TXD_SELECT_INPUT — LPUART2_TXD_SELECT_INPUT DAISY Register
  [0] DAISY — Selecting Pads Involved in Daisy Chain.
    0=GPIO_AD_00_ALT0 (Selecting Pad: GPIO_AD_00 for Mode: ALT0); 1=GPIO_SD_10_ALT2 (Selecting Pad: GPIO_SD_10 for Mode: ALT2)
0x200 LPUART3_RXD_SELECT_INPUT — LPUART3_RXD_SELECT_INPUT DAISY Register
  [1:0] DAISY — Selecting Pads Involved in Daisy Chain.
    0=GPIO_AD_07_ALT1 (Selecting Pad: GPIO_AD_07 for Mode: ALT1); 1=GPIO_11_ALT0 (Selecting Pad: GPIO_11 for Mode: ALT0); 2=GPIO_07_ALT3 (Selecting Pad: GPIO_07 for Mode: ALT3)
0x204 LPUART3_TXD_SELECT_INPUT — LPUART3_TXD_SELECT_INPUT DAISY Register
  [1:0] DAISY — Selecting Pads Involved in Daisy Chain.
    0=GPIO_AD_08_ALT1 (Selecting Pad: GPIO_AD_08 for Mode: ALT1); 1=GPIO_12_ALT0 (Selecting Pad: GPIO_12 for Mode: ALT0); 2=GPIO_08_ALT3 (Selecting Pad: GPIO_08 for Mode: ALT3)
0x208 LPUART4_RXD_SELECT_INPUT — LPUART4_RXD_SELECT_INPUT DAISY Register
  [0] DAISY — Selecting Pads Involved in Daisy Chain.
    0=GPIO_AD_01_ALT0 (Selecting Pad: GPIO_AD_01 for Mode: ALT0); 1=GPIO_05_ALT3 (Selecting Pad: GPIO_05 for Mode: ALT3)
0x20C LPUART4_TXD_SELECT_INPUT — LPUART4_TXD_SELECT_INPUT DAISY Register
  [0] DAISY — Selecting Pads Involved in Daisy Chain.
    0=GPIO_AD_02_ALT0 (Selecting Pad: GPIO_AD_02 for Mode: ALT0); 1=GPIO_06_ALT3 (Selecting Pad: GPIO_06 for Mode: ALT3)
0x210 NMI_GLUE_NMI_SELECT_INPUT — NMI_GLUE_NMI_SELECT_INPUT DAISY Register
  [0] DAISY — Selecting Pads Involved in Daisy Chain.
    0=GPIO_AD_13_ALT6 (Selecting Pad: GPIO_AD_13 for Mode: ALT6); 1=GPIO_AD_00_ALT6 (Selecting Pad: GPIO_AD_00 for Mode: ALT6)
0x214 SPDIF_IN1_SELECT_INPUT — SPDIF_IN1_SELECT_INPUT DAISY Register
  [0] DAISY — Selecting Pads Involved in Daisy Chain.
    0=GPIO_10_ALT6 (Selecting Pad: GPIO_10 for Mode: ALT6); 1=GPIO_04_ALT4 (Selecting Pad: GPIO_04 for Mode: ALT4)
0x218 SPDIF_TX_CLK2_SELECT_INPUT — SPDIF_TX_CLK2_SELECT_INPUT DAISY Register
  [0] DAISY — Selecting Pads Involved in Daisy Chain.
    0=GPIO_12_ALT6 (Selecting Pad: GPIO_12 for Mode: ALT6); 1=GPIO_06_ALT4 (Selecting Pad: GPIO_06 for Mode: ALT4)
0x21C USB_OTG_OC_SELECT_INPUT — USB_OTG_OC_SELECT_INPUT DAISY Register
  [0] DAISY — Selecting Pads Involved in Daisy Chain.
    0=GPIO_AD_01_ALT6 (Selecting Pad: GPIO_AD_01 for Mode: ALT6); 1=GPIO_12_ALT3 (Selecting Pad: GPIO_12 for Mode: ALT3)
0x220 XEV_GLUE_RXEV_SELECT_INPUT — XEV_GLUE_RXEV_SELECT_INPUT DAISY Register
  [0] DAISY — Selecting Pads Involved in Daisy Chain.
    0=GPIO_AD_07_ALT2 (Selecting Pad: GPIO_AD_07 for Mode: ALT2); 1=GPIO_SD_00_ALT2 (Selecting Pad: GPIO_SD_00 for Mode: ALT2)
